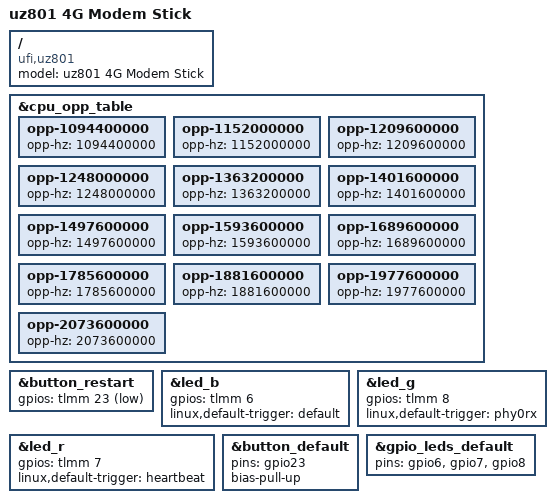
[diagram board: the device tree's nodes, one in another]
// SPDX-License-Identifier: GPL-2.0-only

/dts-v1/;

#include "msm8916-ufi.dtsi"

/ {
	model = "uz801 4G Modem Stick";
	compatible = "ufi,uz801", "qcom,msm8916", "lk2nd,device";
};

&cpu_opp_table {
	opp-1094400000 {
		opp-hz = /bits/ 64 <1094400000>;
	};
	opp-1152000000 {
		opp-hz = /bits/ 64 <1152000000>;
	};
	opp-1209600000 {
		opp-hz = /bits/ 64 <1209600000>;
	};
	opp-1248000000 {
		opp-hz = /bits/ 64 <1248000000>;
	};
	opp-1363200000 {
		opp-hz = /bits/ 64 <1363200000>;
	};
	opp-1401600000 {
		opp-hz = /bits/ 64 <1401600000>;
	};
	opp-1497600000 {
		opp-hz = /bits/ 64 <1497600000>;
	};
	opp-1593600000 {
		opp-hz = /bits/ 64 <1593600000>;
	};
	opp-1689600000 {
		opp-hz = /bits/ 64 <1689600000>;
	};
	opp-1785600000 {
		opp-hz = /bits/ 64 <1785600000>;
	};
	opp-1881600000 {
		opp-hz = /bits/ 64 <1881600000>;
	};
	opp-1977600000 {
		opp-hz = /bits/ 64 <1977600000>;
	};
	opp-2073600000 {
		opp-hz = /bits/ 64 <2073600000>;
	};
};

&button_restart {
	gpios = <&tlmm 23 GPIO_ACTIVE_LOW>;
};

&led_b {
	gpios = <&tlmm 6 GPIO_ACTIVE_HIGH>;
	linux,default-trigger = "default";
};

&led_g {
	gpios = <&tlmm 8 GPIO_ACTIVE_HIGH>;
	linux,default-trigger = "phy0rx";
};

&led_r {
	gpios = <&tlmm 7 GPIO_ACTIVE_HIGH>;
	linux,default-trigger = "heartbeat";
};

&button_default {
	pins = "gpio23";
	bias-pull-up;
};

&gpio_leds_default {
	pins = "gpio6", "gpio7", "gpio8";
};
